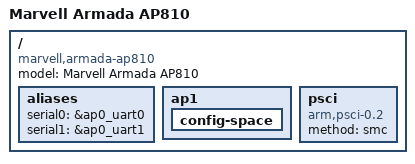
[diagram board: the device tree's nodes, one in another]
/*
 * Copyright (C) 2018 Marvell International Ltd.
 *
 * SPDX-License-Identifier:    GPL-2.0
 * https://spdx.org/licenses
 */

/*
 * Device Tree file for the Armada 8160 SoC, made of dual AP810 only.
 */

#include "armada-common.dtsi"
#include "armada-8kp.dtsi"

/dts-v1/;

#define AP_NUM			0
#define AP810_NAME		ap0
#define AP810_BASE		0xe8000000

#include "armada-ap810.dtsi"

#undef AP_NUM
#undef AP810_NAME
#undef AP810_BASE

#define AP_NUM			1
#define AP810_NAME		ap1
#define AP810_BASE		0xe4000000

#include "armada-ap810.dtsi"

#undef AP_NUM
#undef AP810_NAME
#undef AP810_BASE

/ {
	model = "Marvell Armada AP810";
	compatible = "marvell,armada-ap810";
	#address-cells = <2>;
	#size-cells = <2>;

	aliases {
		serial0 = &ap0_uart0;
		serial1 = &ap0_uart1;
	};

	ap1 {
		config-space {
			/delete-node/ sar-reg@6F8200;
		};
	};

	psci {
		compatible = "arm,psci-0.2";
		method = "smc";
	};

};
